# RT584ZCM33 register map
Series: ARMv8-M Mainline; File version: 1.0
CPU: CM33 r0p0, little endian, MPU, no FPU, VTOR, 3 interrupt priority bits
Registers are 32-bit, read-write, reset 0x0 unless marked. A register's access mark holds for its fields unless they carry their own. Offsets are from the block's base; [hi:lo] are bit positions; {n}, {i} and the like mark numbered series; <NAME> marks a mode.

## SADC_Non-Secure — SADC Non-Secure Register block
Base 0x4002F000
Same registers: SADC_Secure 0x5002F000
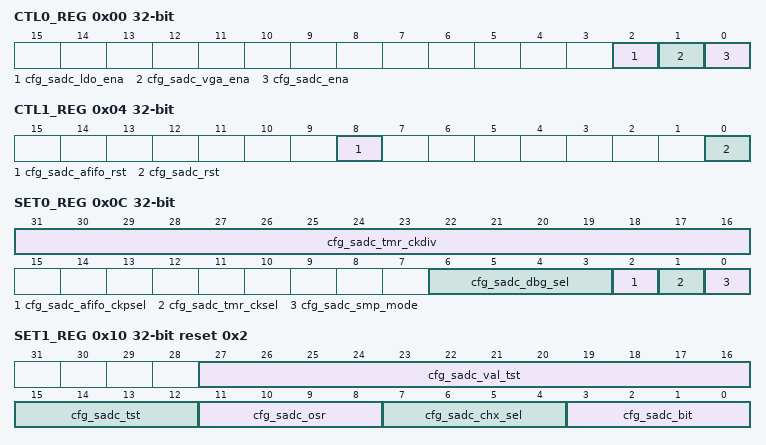
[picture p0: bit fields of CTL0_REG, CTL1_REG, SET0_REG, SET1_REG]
0x00 CTL0_REG — ctl0
  [2] cfg_sadc_ldo_ena — Enable SADC LDO, only work when cfg_sadc_tst[2] = 1 0: disable 1: enable
    0=B_2_ITEM0 (disable); 1=B_2_ITEM1 (enable)
  [1] cfg_sadc_vga_ena — Enable SADC VGA, only work when cfg_sadc_tst[2] = 1 0: disable 1: enable
    0=B_1_ITEM0 (disable); 1=B_1_ITEM1 (enable)
  [0] cfg_sadc_ena — Enable SADC 0: disable 1: enable
    0=B_0_ITEM0 (disable); 1=B_0_ITEM1 (enable)
0x04 CTL1_REG wo — ctl1
  [8] cfg_sadc_afifo_rst — Write 1 to reset SADC FIFO
    0=B_8 (Write 1 to reset SADC FIFO)
  [0] cfg_sadc_rst — Write 1 to reset SADC
    0=B_0 (Write 1 to reset SADC)
0x08 CTL2_REG wo — ctl2
  [0] cfg_sadc_start — Write 1 to start SADC operation
    0=B_0 (Write 1 to start SADC operation)
0x0C SET0_REG — set0
  [31:16] cfg_sadc_tmr_ckdiv — Timer rate configuration Timer rate = timer clock / (cfg_sadc_ckdiv+1) where cfg_sadc_ckdiv = 2 to 65535
  [6:3] cfg_sadc_dbg_sel — Debug monitor selection
    0=B_3_to_6 (Debug monitor selection)
  [2] cfg_sadc_afifo_ckpsel — AFIFO Clock phase selection 0: Write AFIFO at rising edge of clock 1: Write AFIFO at falling edge of clock
    0=B_2_ITEM0 (Write AFIFO at rising edge of clock); 1=B_2_ITEM1 (Write AFIFO at falling edge of clock)
  [1] cfg_sadc_tmr_cksel — Timer clock source selection 0: System clock 1: Slow clock
    0=B_1_ITEM0 (System clock); 1=B_1_ITEM1 (Slow clock)
  [0] cfg_sadc_smp_mode — Sample rate mode 0: Sample rate depends on software start SADC, cfg_sadc_start 1: Sample rate depends on timer rate
    0=B_0_ITEM0 (Sample rate depends on software start SADC, cfg_sadc_start); 1=B_0_ITEM1 (Sample rate depends on timer rate)
0x10 SET1_REG reset 0x2 — set1
  [27:16] cfg_sadc_val_tst — Set SADC adjust value, used for calibration Data format is s1.11.0
  [15:12] cfg_sadc_tst — [0] SADC value bypass 0: sadc_i = sadc_i + cfg_sadc_val_tst, used for calibration 1: sadc_i = cfg_sadc_val_tst, used for bypass [1] SADC MSB bit inversion 0: disable 1: bit reverse [2] SADC control mode 0: normal mode, control by digital 1: manual mode, control by cfg_sadc_chx_sel and cfg_sadc_ena [3] NoUse
    0=B_12_to_15 ([0] SADC value bypass 0: sadc_i = sadc_i + cfg_sadc_val_tst, used for calibration 1: sadc_i = cfg_sadc_val_tst, used for bypass [1] SADC MSB bit inversion 0: disable 1: bit reverse [2] SADC control mode 0: normal mode, control by digital 1: manual mode, control by cfg_sadc_chx_sel and cfg_sadc_ena [3] NoUse)
  [11:8] cfg_sadc_osr — Oversample rate selection 0: No oversample 1: Oversample by 2 2: Oversample by 4 3: Oversample by 8 4: Oversample by 16 5: Oversample by 32 6: Oversample by 64 7: Oversample by 128 8: Oversample by 256 Others: reserved
    0=B_8_to_11 (Oversample rate selection 0: No oversample 1: Oversample by 2 2: Oversample by 4 3: Oversample by 8 4: Oversample by 16 5: Oversample by 32 6: Oversample by 64 7: Oversample by 128 8: Oversample by 256 Others: reserved)
  [7:4] cfg_sadc_chx_sel — At test mode, select from CH0 to CH9. For internal debug only.
    0=B_4_to_7 (At test mode, select from CH0 to CH9. For internal debug only.)
  [3:0] cfg_sadc_bit — SAC output Resolution 0: 8-bit 1: 10-bit 2: 12-bit 3: 14-bit (oversample)
    0=B_0_to_3 (SAC output Resolution 0: 8-bit 1: 10-bit 2: 12-bit 3: 14-bit (oversample))
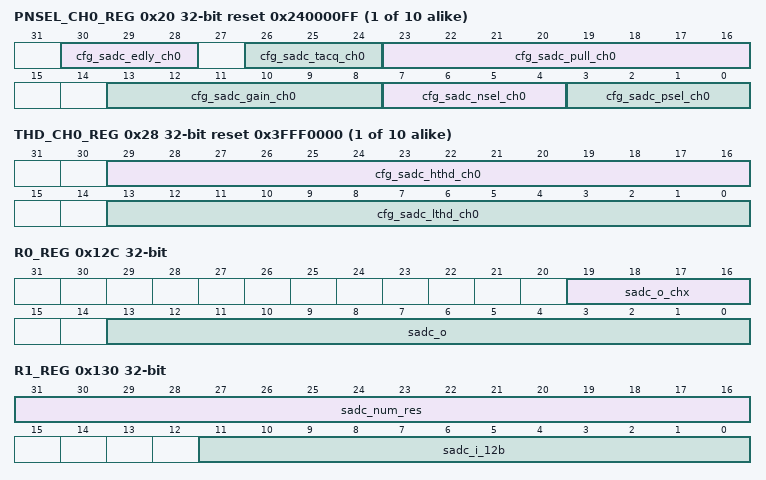
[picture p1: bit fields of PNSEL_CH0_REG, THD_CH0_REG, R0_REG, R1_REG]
{0x20+0x10*i} PNSEL_CH{i}_REG reset 0x240000FF (i=0..9) — pnsel ch{i}
  [30:28] cfg_sadc_edly_ch{i} — SADC end delay time for system clock 32M 0: 0.3us 1: 1us 2: 2us 3: 3us 4: 4us 5: 8us 6: 12us 7: 16us
    0=B_28_to_30_ITEM0 (0.3us); {v}=B_28_to_30_ITEM{v} ({v}us) (v=1..4); 5=B_28_to_30_ITEM5 (8us); 6=B_28_to_30_ITEM6 (12us); 7=B_28_to_30_ITEM7 (16us)
  [26:24] cfg_sadc_tacq_ch{i} — SADC result acquisition time for system clock 32M 0: 0.3us 1: 1us 2: 2us 3: 3us 4: 4us 5: 8us 6: 12us 7: 16us
    0=B_24_to_26_ITEM0 (0.3us); {v}=B_24_to_26_ITEM{v} ({v}us) (v=1..4); 5=B_24_to_26_ITEM5 (8us); 6=B_24_to_26_ITEM6 (12us); 7=B_24_to_26_ITEM7 (16us)
  [23:16] cfg_sadc_pull_ch{i} — Set the corresponding bit to high to enable following functions. cfg_sadc_pull_ch0[0] : Pull the P input to high cfg_sadc_pull_ch0[1] : Pull the P input to low cfg_sadc_pull_ch0[2] : Pull the N input to high cfg_sadc_pull_ch0[3] : Pull the N input to low cfg_sadc_pull_ch0[4] : Short the P input to VDD cfg_sadc_pull_ch0[5] : Short the P input to GROUND cfg_sadc_pull_ch0[6] : Short the N input to VDD cfg_sadc_pull_ch0[7] : Short the N input to GROUND
    0=B_16_to_23 (Set the corresponding bit to high to enable following functions. cfg_sadc_pull_ch0[0] : Pull the P input to high cfg_sadc_pull_ch0[1] : Pull the P input to low cfg_sadc_pull_ch0[2] : Pull the N input to high cfg_sadc_pull_ch0[3] : Pull the N input to low cfg_sadc_pull_ch0[4] : Short the P input to VDD cfg_sadc_pull_ch0[5] : Short the P input to GROUND cfg_sadc_pull_ch0[6] : Short the N input to VDD cfg_sadc_pull_ch0[7] : Short the N input to GROUND)
  [13:8] cfg_sadc_gain_ch{i} — [3:0] VGA gain selection, +3dB/step [5:4] VGA gain selection, +6dB/step
    0=B_8_to_13 ([3:0] VGA gain selection, +3dB/step [5:4] VGA gain selection, +6dB/step)
  [7:4] cfg_sadc_nsel_ch{i} — Select P channel inputs of AUX ADC. Depends on the package, some AIOs may not be available. 0: Select AIO0 1: Select AIO1 2: Select AIO2 3: Select AIO3 4: Select AIO4 5: Select AIO5 6: Select AIO6 7: Select AIO7 8: Select Temperature Sensor P output (temp_p) 9: Bypass VGA, for debug only. 10: Select Battery voltage. Others Disabled.
    0=B_4_to_7 (Select P channel inputs of AUX ADC. Depends on the package, some AIOs may not be available. 0: Select AIO0 1: Select AIO1 2: Select AIO2 3: Select AIO3 4: Select AIO4 5: Select AIO5 6: Select AIO6 7: Select AIO7 8: Select Temperature Sensor P output (temp_p) 9: Bypass VGA, for debug only. 10: Select Battery voltage. Others Disabled.)
  [3:0] cfg_sadc_psel_ch{i} — Select N channel inputs of AUX ADC. Depends on the package, some AIOs may not be available. 0: Select AIO0 1: Select AIO1 2: Select AIO2 3: Select AIO3 4: Select AIO4 5: Select AIO5 6: Select AIO6 7: Select AIO7 8: Select Temperature Sensor N output (temp_n) 9: Bypass VGA, for debug only. 10: Select Battery voltage. Others Disabled.
    0=B_0_to_3 (Select N channel inputs of AUX ADC. Depends on the package, some AIOs may not be available. 0: Select AIO0 1: Select AIO1 2: Select AIO2 3: Select AIO3 4: Select AIO4 5: Select AIO5 6: Select AIO6 7: Select AIO7 8: Select Temperature Sensor N output (temp_n) 9: Bypass VGA, for debug only. 10: Select Battery voltage. Others Disabled.)
{0x24+0x10*i} SET_CH{i}_REG reset 0x80000000 (i=0..9) — set ch{i}
  [31] cfg_sadc_burst_ch{i} — SADC Burst mode selection 0: Disable burst mode 1: Select burst mode, SADC take 2^Oversample number of sample and average to send the Memory
    0=B_31_ITEM0 (Disable burst mode); 1=B_31_ITEM1 (Select burst mode, SADC take 2^Oversample number of sample and average to send the Memory)
{0x28+0x10*i} THD_CH{i}_REG reset 0x3FFF0000 (i=0..9) — thd ch{i}
  [29:16] cfg_sadc_hthd_ch{i} — SADC high threshold, u0.14.0
  [13:0] cfg_sadc_lthd_ch{i} — SADC low threshold, u0.14.0
0x100 WDMA_CTL0_REG wo — wdma ctl0
  [3:0] cfg_sadc_wdma_ctl0 — Write 1 to start xdma for memory write access.
    0=B_0_to_3 (Write 1 to start xdma for memory write access.)
0x104 WDMA_CTL1_REG wo — wdma ctl1
  [0] cfg_sadc_wdma_ctl1 — Write 1 to reset xdma write access.
    0=B_0 (Write 1 to reset xdma write access.)
0x108 WDMA_SET0_REG — [15:0] Segment size, 4-byte aligned 0: Illegal value Others: 1 to 65535 (Block size < Segment size) [31:16] Block size, 4-byte aligned 0: Single-shot mode Others: 1 to 65535 (Block size < Segment size)
0x10C WDMA_SET1_REG — start address point, 2-byte aligned The 1-LSB bit will be ignored
0x110 WDMA_SET2_REG reset 0x10 — wdma set2
  [7:0] cfg_sadc_wdma_set2 — [0] Set initial address 0: when xdma start, initial address is loaded from ptr 1: when xdma reset, initial address is loaded from ptr [3:1] Reserved [5:4] DMA data format 0: word, 4-bytes aligned 1: halfword, 2-bytes aligned 2/3: 1-byte aligned [7:6] Reserved
    0=B_0_to_7 ([0] Set initial address 0: when xdma start, initial address is loaded from ptr 1: when xdma reset, initial address is loaded from ptr [3:1] Reserved [5:4] DMA data format 0: word, 4-bytes aligned 1: halfword, 2-bytes aligned 2/3: 1-byte aligned [7:6] Reserved)
0x114 WDMA_R0_REG ro — Status of xdma next pointer address
0x118 WDMA_R1_REG ro — [0] xdma interrupt status [1] xdma error interrupt status [2] OR(xdma interrupt status, xdma error interrupt status) [9:8] xdma counter status, used for ping-pong buffer to check buffer status [16] xdma enable [17] xdma_done [19:18] xdma_status
0x120 INT_CLEAR_REG wo — int clear
  [27:0] cfg_sadc_int_clear — [0] Clear SADC_WDMA interrupt 1: clear [1] Clear SADC_WDMA error interrupt 1: clear [2] Clear SADC Done interrupt 1: clear [3] Clear SADC Valid interrupt 1: clear [4] Clear SADC Mode Done interrupt 1: clear [7:5] NoUse [17:8] Clear SADC monitor Low interrupt for CH9:0 1: clear [27:18] Clear SADC monitor High interrupt for CH9:0 1: clear
0x124 INT_MASK_REG reset 0xFFFFFE6 — int mask
  [27:0] cfg_sadc_int_mask — [0] Mask SADC_WDMA interrupt 0: No mask 1: Mask [1] Mask SADC_WDMA error interrupt 0: No mask 1: Mask [2] Mask SADC Done interrupt 0: No mask 1: Mask [3] Mask SADC Valid interrupt 0: No mask 1: Mask [4] Mask SADC Mode Done interrupt 0: No mask 1: Mask [7:5] NoUse [17:8] Mask SADC monitor Low interrupt for CH9:0 0: No mask 1: Mask [27:18] Mask SADC monitor High interrupt for CH9:0 0: No mask 1: Mask
0x128 INT_STATUS_REG ro — int status
  [27:0] cfg_sadc_int_status — [0] Status of SADC_WDMA interrupt [1] Status of SADC_WDMA error interrupt [2] Status of SADC Done interrupt [3] Status of SADC Valid interrupt [4] Status os SADC Mode Done interrupt [7:5] NoUse [17:8] Status of SADC monitor Low interrupt for CH9:0 [27:18] Status of SADC monitor High interrupt for CH9:0
0x12C R0_REG ro — r0
  [19:16] sadc_o_chx — SADC channel index
    0=B_16_to_19 (SADC channel index)
  [13:0] sadc_o — SADC output value after digital control and oversampling, data format is u0.14.0;
0x130 R1_REG ro — r1
  [31:16] sadc_num_res — Number of SADC result write into WDMA since last sadc_start trigger
  [11:0] sadc_i_12b — SADC output value after digital control and No oversampling, data format is u0.14.0
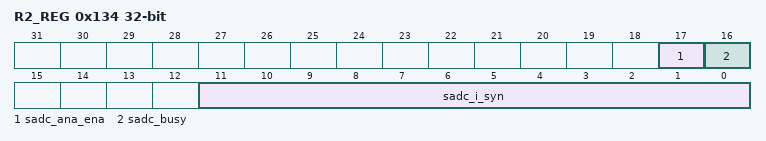
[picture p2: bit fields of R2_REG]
0x134 R2_REG ro — r2
  [17] sadc_ana_ena — SADC analog enable
    0=B_17 (SADC analog enable)
  [16] sadc_busy — SADC mode control busy 0: idle 1: busy
    0=B_16_ITEM0 (idle); 1=B_16_ITEM1 (busy)
  [11:0] sadc_i_syn — SADC result via AFIFO, data format is u0.12.0
